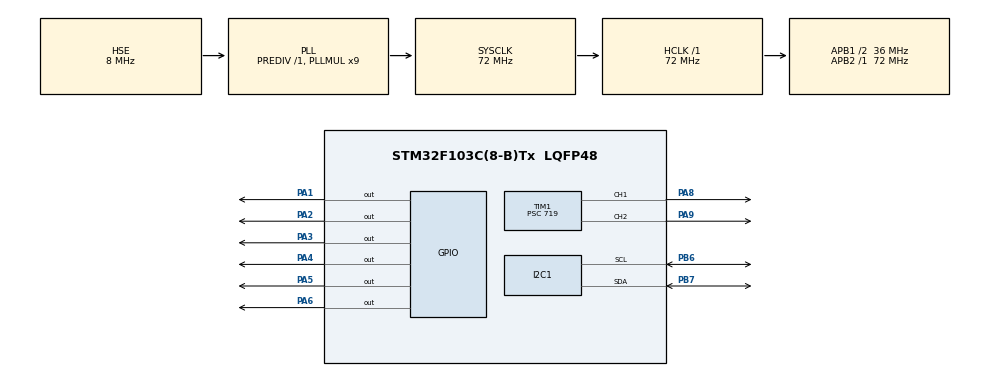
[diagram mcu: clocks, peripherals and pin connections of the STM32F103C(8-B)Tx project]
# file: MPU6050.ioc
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Dma.I2C1_RX.0.Direction=DMA_PERIPH_TO_MEMORY
Dma.I2C1_RX.0.Instance=DMA1_Channel7
Dma.I2C1_RX.0.MemDataAlignment=DMA_MDATAALIGN_BYTE
Dma.I2C1_RX.0.MemInc=DMA_MINC_ENABLE
Dma.I2C1_RX.0.Mode=DMA_NORMAL
Dma.I2C1_RX.0.PeriphDataAlignment=DMA_PDATAALIGN_BYTE
Dma.I2C1_RX.0.PeriphInc=DMA_PINC_DISABLE
Dma.I2C1_RX.0.Priority=DMA_PRIORITY_LOW
Dma.I2C1_TX.1.Direction=DMA_MEMORY_TO_PERIPH
Dma.I2C1_TX.1.Instance=DMA1_Channel6
Dma.I2C1_TX.1.MemDataAlignment=DMA_MDATAALIGN_BYTE
Dma.I2C1_TX.1.MemInc=DMA_MINC_ENABLE
Dma.I2C1_TX.1.Mode=DMA_NORMAL
Dma.I2C1_TX.1.PeriphDataAlignment=DMA_PDATAALIGN_BYTE
Dma.I2C1_TX.1.PeriphInc=DMA_PINC_DISABLE
Dma.I2C1_TX.1.Priority=DMA_PRIORITY_LOW
Dma.Request0=I2C1_RX
Dma.Request1=I2C1_TX
I2C1.I2C_Mode=I2C_Fast
Mcu.Family=STM32F1
Mcu.Name=STM32F103C(8-B)Tx
Mcu.Package=LQFP48
NVIC.DMA1_Channel6_IRQn=true\:0\:0\:false\:false\:true\:false\:true\:true
NVIC.DMA1_Channel7_IRQn=true\:0\:0\:false\:false\:true\:false\:true\:true
NVIC.FLASH_IRQn=true\:0\:0\:false\:false\:true\:true\:true\:true
NVIC.I2C1_ER_IRQn=true\:0\:0\:false\:false\:true\:true\:true\:true
NVIC.I2C1_EV_IRQn=true\:0\:0\:false\:false\:true\:true\:true\:true
NVIC.PVD_IRQn=true\:0\:0\:false\:false\:true\:true\:true\:true
NVIC.PriorityGroup=NVIC_PRIORITYGROUP_4
NVIC.RCC_IRQn=true\:0\:0\:false\:false\:true\:true\:false\:true
NVIC.TIM1_BRK_IRQn=true\:0\:0\:false\:false\:true\:true\:true\:true
NVIC.TIM1_CC_IRQn=true\:0\:0\:false\:false\:true\:true\:true\:true
NVIC.TIM1_TRG_COM_IRQn=true\:0\:0\:false\:false\:true\:true\:true\:true
NVIC.TIM1_UP_IRQn=true\:0\:0\:false\:false\:true\:true\:true\:true
PA1.Signal=GPIO_Output
PA13.Mode=Serial_Wire
PA13.Signal=SYS_JTMS-SWDIO
PA14.Mode=Serial_Wire
PA14.Signal=SYS_JTCK-SWCLK
PA2.Signal=GPIO_Output
PA3.Signal=GPIO_Output
PA4.Signal=GPIO_Output
PA5.Signal=GPIO_Output
PA6.Signal=GPIO_Output
PA8.Signal=S_TIM1_CH1
PA9.Signal=S_TIM1_CH2
PB6.Mode=I2C
PB6.Signal=I2C1_SCL
PB7.Mode=I2C
PB7.Signal=I2C1_SDA
PD0-OSC_IN.Mode=HSE-External-Oscillator
PD0-OSC_IN.Signal=RCC_OSC_IN
PD1-OSC_OUT.Mode=HSE-External-Oscillator
PD1-OSC_OUT.Signal=RCC_OSC_OUT
ProjectManager.HeapSize=0x200
ProjectManager.StackSize=0x400
ProjectManager.TargetToolchain=STM32CubeIDE
RCC.AHBFreq_Value=72000000
RCC.APB1CLKDivider=RCC_HCLK_DIV2
RCC.APB1Freq_Value=36000000
RCC.APB1TimFreq_Value=72000000
RCC.APB2Freq_Value=72000000
RCC.APB2TimFreq_Value=72000000
RCC.HCLKFreq_Value=72000000
RCC.PLLMUL=RCC_PLL_MUL9
RCC.PLLSourceVirtual=RCC_PLLSOURCE_HSE
RCC.SYSCLKFreq_VALUE=72000000
RCC.SYSCLKSource=RCC_SYSCLKSOURCE_PLLCLK
RCC.USBFreq_Value=48000000
RCC.USBPrescaler=RCC_USBCLKSOURCE_PLL_DIV1_5
SH.S_TIM1_CH1.0=TIM1_CH1,PWM Generation1 CH1
SH.S_TIM1_CH2.0=TIM1_CH2,PWM Generation2 CH2
TIM1.Channel-PWM\ Generation1\ CH1=TIM_CHANNEL_1
TIM1.Channel-PWM\ Generation2\ CH2=TIM_CHANNEL_2
TIM1.Period=99
TIM1.Prescaler=719
TIM1.Pulse-PWM\ Generation1\ CH1=0
TIM1.Pulse-PWM\ Generation2\ CH2=0
VP_TIM1_VS_ClockSourceINT.Mode=Internal
board=custom

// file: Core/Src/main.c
/* USER CODE BEGIN Header */
/**
  ******************************************************************************
  * @file           : main.c
  * @brief          : Main program body
  ******************************************************************************
  * @attention
  *
  * Copyright (c) 2025 STMicroelectronics.
  * All rights reserved.
  *
  * This software is licensed under terms that can be found in the LICENSE file
  * in the root directory of this software component.
  * If no LICENSE file comes with this software, it is provided AS-IS.
  *
  ******************************************************************************
  */
/* USER CODE END Header */
#include "main.h"

/* USER CODE BEGIN Includes */
#include "BalanceApp.h"
/* USER CODE END Includes */

I2C_HandleTypeDef hi2c1;
DMA_HandleTypeDef hdma_i2c1_rx;
DMA_HandleTypeDef hdma_i2c1_tx;

TIM_HandleTypeDef htim1;

void SystemClock_Config(void);
static void MX_GPIO_Init(void);
static void MX_DMA_Init(void);
static void MX_I2C1_Init(void);
static void MX_TIM1_Init(void);

int main(void)
{

  /* MCU Configuration--------------------------------------------------------*/

  /* Reset of all peripherals, Initializes the Flash interface and the Systick. */
  HAL_Init();

  /* Configure the system clock */
  SystemClock_Config();

  /* Initialize all configured peripherals */
  MX_GPIO_Init();
  MX_DMA_Init();
  MX_I2C1_Init();
  MX_TIM1_Init();
  /* USER CODE BEGIN 2 */

  if (BalanceApp_Init(&hi2c1, &htim1) != 0U)
  {
    Error_Handler();
  }

  /* USER CODE END 2 */

  /* Infinite loop */
  while (1)
  {

    /* USER CODE BEGIN 3 */
    BalanceApp_MainFunction();

  }
  /* USER CODE END 3 */
}

void SystemClock_Config(void)
{
  RCC_OscInitTypeDef RCC_OscInitStruct = {0};
  RCC_ClkInitTypeDef RCC_ClkInitStruct = {0};

  /** Initializes the RCC Oscillators according to the specified parameters
  * in the RCC_OscInitTypeDef structure.
  */
  RCC_OscInitStruct.OscillatorType = RCC_OSCILLATORTYPE_HSE;
  RCC_OscInitStruct.HSEState = RCC_HSE_ON;
  RCC_OscInitStruct.HSEPredivValue = RCC_HSE_PREDIV_DIV1;
  RCC_OscInitStruct.HSIState = RCC_HSI_ON;
  RCC_OscInitStruct.PLL.PLLState = RCC_PLL_ON;
  RCC_OscInitStruct.PLL.PLLSource = RCC_PLLSOURCE_HSE;
  RCC_OscInitStruct.PLL.PLLMUL = RCC_PLL_MUL9;
  if (HAL_RCC_OscConfig(&RCC_OscInitStruct) != HAL_OK)
  {
    Error_Handler();
  }

  /** Initializes the CPU, AHB and APB buses clocks
  */
  RCC_ClkInitStruct.ClockType = RCC_CLOCKTYPE_HCLK|RCC_CLOCKTYPE_SYSCLK
                              |RCC_CLOCKTYPE_PCLK1|RCC_CLOCKTYPE_PCLK2;
  RCC_ClkInitStruct.SYSCLKSource = RCC_SYSCLKSOURCE_PLLCLK;
  RCC_ClkInitStruct.AHBCLKDivider = RCC_SYSCLK_DIV1;
  RCC_ClkInitStruct.APB1CLKDivider = RCC_HCLK_DIV2;
  RCC_ClkInitStruct.APB2CLKDivider = RCC_HCLK_DIV1;

  if (HAL_RCC_ClockConfig(&RCC_ClkInitStruct, FLASH_LATENCY_2) != HAL_OK)
  {
    Error_Handler();
  }
}

static void MX_I2C1_Init(void)
{

  hi2c1.Instance = I2C1;
  hi2c1.Init.ClockSpeed = 400000;
  hi2c1.Init.DutyCycle = I2C_DUTYCYCLE_2;
  hi2c1.Init.OwnAddress1 = 0;
  hi2c1.Init.AddressingMode = I2C_ADDRESSINGMODE_7BIT;
  hi2c1.Init.DualAddressMode = I2C_DUALADDRESS_DISABLE;
  hi2c1.Init.OwnAddress2 = 0;
  hi2c1.Init.GeneralCallMode = I2C_GENERALCALL_DISABLE;
  hi2c1.Init.NoStretchMode = I2C_NOSTRETCH_DISABLE;
  if (HAL_I2C_Init(&hi2c1) != HAL_OK)
  {
    Error_Handler();
  }

}

static void MX_TIM1_Init(void)
{

  TIM_ClockConfigTypeDef sClockSourceConfig = {0};
  TIM_MasterConfigTypeDef sMasterConfig = {0};
  TIM_OC_InitTypeDef sConfigOC = {0};
  TIM_BreakDeadTimeConfigTypeDef sBreakDeadTimeConfig = {0};

  htim1.Instance = TIM1;
  htim1.Init.Prescaler = 719;
  htim1.Init.CounterMode = TIM_COUNTERMODE_UP;
  htim1.Init.Period = 99;
  htim1.Init.ClockDivision = TIM_CLOCKDIVISION_DIV1;
  htim1.Init.RepetitionCounter = 0;
  htim1.Init.AutoReloadPreload = TIM_AUTORELOAD_PRELOAD_DISABLE;
  if (HAL_TIM_Base_Init(&htim1) != HAL_OK)
  {
    Error_Handler();
  }
  sClockSourceConfig.ClockSource = TIM_CLOCKSOURCE_INTERNAL;
  if (HAL_TIM_ConfigClockSource(&htim1, &sClockSourceConfig) != HAL_OK)
  {
    Error_Handler();
  }
  if (HAL_TIM_PWM_Init(&htim1) != HAL_OK)
  {
    Error_Handler();
  }
  sMasterConfig.MasterOutputTrigger = TIM_TRGO_RESET;
  sMasterConfig.MasterSlaveMode = TIM_MASTERSLAVEMODE_DISABLE;
  if (HAL_TIMEx_MasterConfigSynchronization(&htim1, &sMasterConfig) != HAL_OK)
  {
    Error_Handler();
  }
  sConfigOC.OCMode = TIM_OCMODE_PWM1;
  sConfigOC.Pulse = 0;
  sConfigOC.OCPolarity = TIM_OCPOLARITY_HIGH;
  sConfigOC.OCNPolarity = TIM_OCNPOLARITY_HIGH;
  sConfigOC.OCFastMode = TIM_OCFAST_DISABLE;
  sConfigOC.OCIdleState = TIM_OCIDLESTATE_RESET;
  sConfigOC.OCNIdleState = TIM_OCNIDLESTATE_RESET;
  if (HAL_TIM_PWM_ConfigChannel(&htim1, &sConfigOC, TIM_CHANNEL_1) != HAL_OK)
  {
    Error_Handler();
  }
  if (HAL_TIM_PWM_ConfigChannel(&htim1, &sConfigOC, TIM_CHANNEL_2) != HAL_OK)
  {
    Error_Handler();
  }
  sBreakDeadTimeConfig.OffStateRunMode = TIM_OSSR_DISABLE;
  sBreakDeadTimeConfig.OffStateIDLEMode = TIM_OSSI_DISABLE;
  sBreakDeadTimeConfig.LockLevel = TIM_LOCKLEVEL_OFF;
  sBreakDeadTimeConfig.DeadTime = 0;
  sBreakDeadTimeConfig.BreakState = TIM_BREAK_DISABLE;
  sBreakDeadTimeConfig.BreakPolarity = TIM_BREAKPOLARITY_HIGH;
  sBreakDeadTimeConfig.AutomaticOutput = TIM_AUTOMATICOUTPUT_DISABLE;
  if (HAL_TIMEx_ConfigBreakDeadTime(&htim1, &sBreakDeadTimeConfig) != HAL_OK)
  {
    Error_Handler();
  }
  HAL_TIM_MspPostInit(&htim1);

}

static void MX_DMA_Init(void)
{

  /* DMA controller clock enable */
  __HAL_RCC_DMA1_CLK_ENABLE();

  /* DMA interrupt init */
  /* DMA1_Channel6_IRQn interrupt configuration */
  HAL_NVIC_SetPriority(DMA1_Channel6_IRQn, 0, 0);
  HAL_NVIC_EnableIRQ(DMA1_Channel6_IRQn);
  /* DMA1_Channel7_IRQn interrupt configuration */
  HAL_NVIC_SetPriority(DMA1_Channel7_IRQn, 0, 0);
  HAL_NVIC_EnableIRQ(DMA1_Channel7_IRQn);

}

static void MX_GPIO_Init(void)
{
  GPIO_InitTypeDef GPIO_InitStruct = {0};

  /* GPIO Ports Clock Enable */
  __HAL_RCC_GPIOD_CLK_ENABLE();
  __HAL_RCC_GPIOA_CLK_ENABLE();
  __HAL_RCC_GPIOB_CLK_ENABLE();

  /*Configure GPIO pin Output Level */
  HAL_GPIO_WritePin(GPIOA, GPIO_PIN_1|GPIO_PIN_2|GPIO_PIN_3|GPIO_PIN_4|GPIO_PIN_5|GPIO_PIN_6, GPIO_PIN_RESET);

  /*Configure GPIO pins : PA1 PA2 PA3 PA4 PA5 PA6 */
  GPIO_InitStruct.Pin = GPIO_PIN_1|GPIO_PIN_2|GPIO_PIN_3|GPIO_PIN_4|GPIO_PIN_5|GPIO_PIN_6;
  GPIO_InitStruct.Mode = GPIO_MODE_OUTPUT_PP;
  GPIO_InitStruct.Pull = GPIO_NOPULL;
  GPIO_InitStruct.Speed = GPIO_SPEED_FREQ_LOW;
  HAL_GPIO_Init(GPIOA, &GPIO_InitStruct);

}

/* USER CODE BEGIN 4 */
int _write(int file, char *ptr, int len)
{
  (void)file;
  int DataIdx;

  for (DataIdx = 0; DataIdx < len; DataIdx++)
  {
    ITM_SendChar(*ptr++);
  }
  return len;
}
/* USER CODE END 4 */

void Error_Handler(void)
{
  __disable_irq();
  while (1)
  {
  }
}
